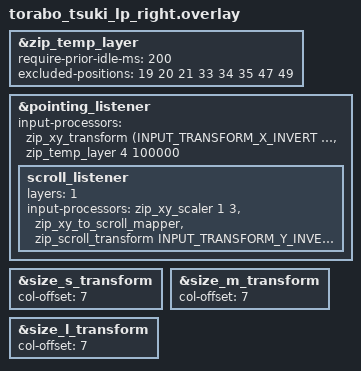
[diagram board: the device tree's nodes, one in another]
#include "torabo_tsuki_lp.dtsi"
#include <input/processors.dtsi>
#include <dt-bindings/zmk/input_transform.h>

&zip_temp_layer {
    require-prior-idle-ms = <200>;
    excluded-positions = <
        19    //U
        20    //I
        21    //O
        33    //J
        34    //K
        35    //L
        47    //M
        49    //.    これらのキー以外を押したら、AML解除
    >;
};

&pointing_listener {
    input-processors = <&zip_xy_transform (INPUT_TRANSFORM_X_INVERT | INPUT_TRANSFORM_Y_INVERT)>,
                       <&zip_temp_layer 4 100000>;    //トラックボールの操作があったらレイヤー１に

//スクロールレイヤー（レイヤー２の時にスクロール）
scroll_listener {
        layers = <1>;
        input-processors = <&zip_xy_scaler 1 3>
        , <&zip_xy_to_scroll_mapper>
        , <&zip_scroll_transform INPUT_TRANSFORM_Y_INVERT>;
    };
};

&size_s_transform {
    col-offset = <7>;
};

&size_m_transform {
    col-offset = <7>;
};

&size_l_transform {
    col-offset = <7>;
};
